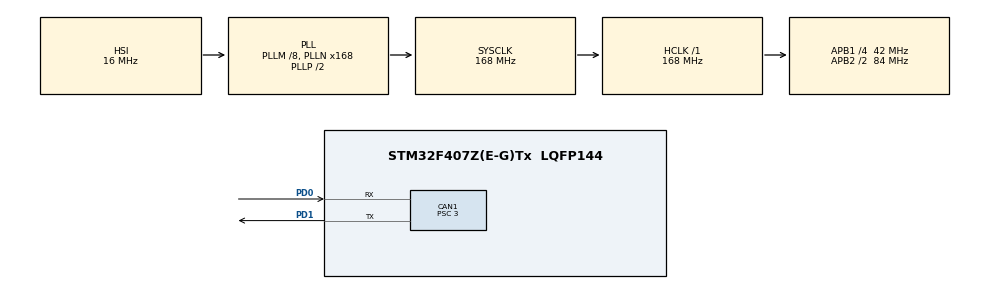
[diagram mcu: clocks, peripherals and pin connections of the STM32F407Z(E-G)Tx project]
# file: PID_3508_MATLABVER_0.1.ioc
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CAN1.BS1=CAN_BS1_9TQ
CAN1.BS2=CAN_BS2_4TQ
CAN1.CalculateBaudRate=1000000
CAN1.CalculateTimeBit=1000
CAN1.CalculateTimeQuantum=71.42857142857143
CAN1.Prescaler=3
Mcu.Family=STM32F4
Mcu.Name=STM32F407Z(E-G)Tx
Mcu.Package=LQFP144
NVIC.CAN1_RX0_IRQn=true\:1\:0\:true\:false\:true\:true\:true\:true
NVIC.CAN1_TX_IRQn=true\:1\:0\:true\:false\:true\:true\:true\:true
NVIC.PriorityGroup=NVIC_PRIORITYGROUP_4
NVIC.TIM1_UP_TIM10_IRQn=true\:0\:0\:false\:false\:true\:true\:true\:true
PA13.Mode=Serial_Wire
PA13.Signal=SYS_JTMS-SWDIO
PA14.Mode=Serial_Wire
PA14.Signal=SYS_JTCK-SWCLK
PD0.Mode=CAN_Activate
PD0.Signal=CAN1_RX
PD1.Mode=CAN_Activate
PD1.Signal=CAN1_TX
PH0-OSC_IN.Mode=HSE-External-Oscillator
PH0-OSC_IN.Signal=RCC_OSC_IN
PH1-OSC_OUT.Mode=HSE-External-Oscillator
PH1-OSC_OUT.Signal=RCC_OSC_OUT
ProjectManager.HeapSize=0x200
ProjectManager.StackSize=0x400
ProjectManager.TargetToolchain=MDK-ARM V5.32
RCC.48MHZClocksFreq_Value=84000000
RCC.AHBFreq_Value=168000000
RCC.APB1CLKDivider=RCC_HCLK_DIV4
RCC.APB1Freq_Value=42000000
RCC.APB1TimFreq_Value=84000000
RCC.APB2CLKDivider=RCC_HCLK_DIV2
RCC.APB2Freq_Value=84000000
RCC.APB2TimFreq_Value=168000000
RCC.CortexFreq_Value=168000000
RCC.HCLKFreq_Value=168000000
RCC.HSE_VALUE=25000000
RCC.HSI_VALUE=16000000
RCC.LSE_VALUE=32768
RCC.PLLM=8
RCC.PLLN=168
RCC.SYSCLKFreq_VALUE=168000000
RCC.SYSCLKSource=RCC_SYSCLKSOURCE_PLLCLK
RCC.VCOOutputFreq_Value=336000000
STMicroelectronics.X-CUBE-ALGOBUILD.1.3.0.LibraryCcDSPOoLibraryJjDSPOoLibrary=true
TIM10.AutoReloadPreload=TIM_AUTORELOAD_PRELOAD_ENABLE
TIM10.Period=1000-1
TIM10.Prescaler=168-1
VP_STMicroelectronics.X-CUBE-ALGOBUILD_VS_DSPOoLibraryJjLibrary_1.3.0_1.3.0.Mode=DSPOoLibraryJjLibrary
VP_TIM10_VS_ClockSourceINT.Mode=Enable_Timer
board=custom

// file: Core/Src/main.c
/* USER CODE BEGIN Header */
/**
  ******************************************************************************
  * @file           : main.c
  * @brief          : Main program body
  ******************************************************************************
  * @attention
  *
  * Copyright (c) 2023 STMicroelectronics.
  * All rights reserved.
  *
  * This software is licensed under terms that can be found in the LICENSE file
  * in the root directory of this software component.
  * If no LICENSE file comes with this software, it is provided AS-IS.
  *
  ******************************************************************************
  */
/* USER CODE END Header */
#include "main.h"
#include "can.h"
#include "tim.h"
#include "gpio.h"

/* USER CODE BEGIN Includes */
#include "Subsystem.h"
#include "arm_math.h"
#include "bsp_can.h"
/* USER CODE END Includes */

/* USER CODE BEGIN PTD */
extern motor_measure_t   *motor_data[4];
/* USER CODE END PTD */

/* USER CODE BEGIN PD */
int TGT = 0;
int ANG_TGT = 0 ;
int output = 0;
/* USER CODE END PD */

void SystemClock_Config(void);

int main(void)
{

  /* MCU Configuration--------------------------------------------------------*/

  /* Reset of all peripherals, Initializes the Flash interface and the Systick. */
  HAL_Init();

  /* Configure the system clock */
  SystemClock_Config();

  /* Initialize all configured peripherals */
  MX_GPIO_Init();
  MX_CAN1_Init();
  MX_TIM10_Init();
  /* USER CODE BEGIN 2 */
	Subsystem_initialize();

	HAL_TIM_Base_Start_IT(&htim10); // 中断

	can_filter_init();
	HAL_CAN_Start(&hcan1);
	HAL_CAN_ActivateNotification(&hcan1, CAN_IT_RX_FIFO0_MSG_PENDING);

	/* USER CODE END 2 */

  /* Infinite loop */
  /* USER CODE BEGIN WHILE */
		// SPD
		rtP.Kp_s = 0.5 ;
		rtP.Ki_s = 0.3 ;
		rtP.Kd_s   = 0 ;

	  //ANG
		rtP.Kp_a = 0.5 ;
		rtP.Ki_a = 0.3 ;
		rtP.Kd_a   = 0.1 ;

		// other things
		rtP.DeadBand = 700;
		rtP.trans  = 1;

	while (1)
  {
    /* USER CODE END WHILE */

  }
}

void SystemClock_Config(void)
{
  RCC_OscInitTypeDef RCC_OscInitStruct = {0};
  RCC_ClkInitTypeDef RCC_ClkInitStruct = {0};

  /** Configure the main internal regulator output voltage
  */
  __HAL_RCC_PWR_CLK_ENABLE();
  __HAL_PWR_VOLTAGESCALING_CONFIG(PWR_REGULATOR_VOLTAGE_SCALE1);

  /** Initializes the RCC Oscillators according to the specified parameters
  * in the RCC_OscInitTypeDef structure.
  */
  RCC_OscInitStruct.OscillatorType = RCC_OSCILLATORTYPE_HSI;
  RCC_OscInitStruct.HSIState = RCC_HSI_ON;
  RCC_OscInitStruct.HSICalibrationValue = RCC_HSICALIBRATION_DEFAULT;
  RCC_OscInitStruct.PLL.PLLState = RCC_PLL_ON;
  RCC_OscInitStruct.PLL.PLLSource = RCC_PLLSOURCE_HSI;
  RCC_OscInitStruct.PLL.PLLM = 8;
  RCC_OscInitStruct.PLL.PLLN = 168;
  RCC_OscInitStruct.PLL.PLLP = RCC_PLLP_DIV2;
  RCC_OscInitStruct.PLL.PLLQ = 4;
  if (HAL_RCC_OscConfig(&RCC_OscInitStruct) != HAL_OK)
  {
    Error_Handler();
  }

  /** Initializes the CPU, AHB and APB buses clocks
  */
  RCC_ClkInitStruct.ClockType = RCC_CLOCKTYPE_HCLK|RCC_CLOCKTYPE_SYSCLK
                              |RCC_CLOCKTYPE_PCLK1|RCC_CLOCKTYPE_PCLK2;
  RCC_ClkInitStruct.SYSCLKSource = RCC_SYSCLKSOURCE_PLLCLK;
  RCC_ClkInitStruct.AHBCLKDivider = RCC_SYSCLK_DIV1;
  RCC_ClkInitStruct.APB1CLKDivider = RCC_HCLK_DIV4;
  RCC_ClkInitStruct.APB2CLKDivider = RCC_HCLK_DIV2;

  if (HAL_RCC_ClockConfig(&RCC_ClkInitStruct, FLASH_LATENCY_5) != HAL_OK)
  {
    Error_Handler();
  }
}

/* USER CODE BEGIN 4 */
void HAL_TIM_PeriodElapsedCallback(TIM_HandleTypeDef *htim)
{

	if(htim == &htim10)
	{

//		//SPD_TEST----------------
//		//update_here
//
//		rtU.status    = 1 ;// speed
//		rtU.speed_rpm = motor_data[0]->speed_rpm;
//		rtU.ecd       = motor_data[0]->ecd;
//		rtU.last_ecd  = motor_data[0]->last_ecd;
//		rtU.target    = TGT;
//		rtU.circle    = 0;
//
//
//		Subsystem_step();
//
//		output = rtY.SPD_OUT ;
//
//		CAN_cmd_chassis(output,0,0,0);
	//------------------------------

		//		//ANG_TEST----------------
		//update_here
		ANG_TGT  = TGT / 360 * 18 * 8191;

		rtU.status    = 2 ;// ANG
		rtU.speed_rpm = motor_data[0]->speed_rpm;
		rtU.ecd       = motor_data[0]->ecd;
		rtU.last_ecd  = motor_data[0]->last_ecd;
		rtU.target    = ANG_TGT;
		rtU.circle    = motor_data[0]->circle;

		Subsystem_step();

		output = rtY.ANG_OUT ;

		motor_data[0]->circle = rtU.circle;

		CAN_cmd_chassis(output,0,0,0);

		// data update
		motor_state_update();

	}

}
/* USER CODE END 4 */

void Error_Handler(void)
{
  __disable_irq();
  while (1)
  {
  }
}
